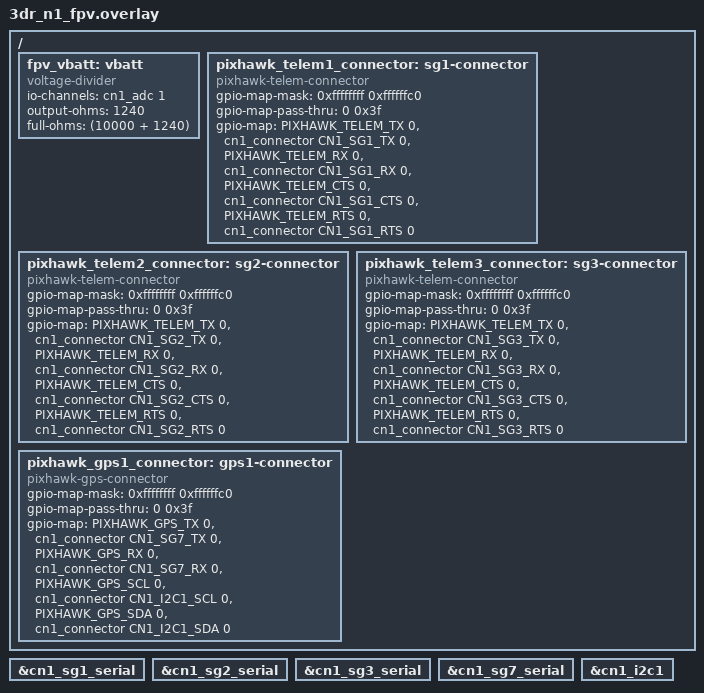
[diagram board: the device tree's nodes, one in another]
/*
 * SPDX-FileCopyrightText: Copyright The Zephyr Project Contributors
 * SPDX-License-Identifier: Apache-2.0
 */

#include <zephyr/dt-bindings/gpio/3dr-control-n1-connector.h>
#include <zephyr/dt-bindings/gpio/pixhawk-connector.h>

/ {
	/*
	 * Battery voltage from the VBATT pads. The resistors are not documented:
	 * these values give the ratio measured on a carrier, 22.5 V reading 2.483 V.
	 */
	fpv_vbatt: vbatt {
		compatible = "voltage-divider";
		io-channels = <&cn1_adc 1>;
		output-ohms = <1240>;
		full-ohms = <(10000 + 1240)>;
	};

	pixhawk_telem1_connector: sg1-connector {
		compatible = "pixhawk-telem-connector";
		#gpio-cells = <2>;
		gpio-map-mask = <0xffffffff 0xffffffc0>;
		gpio-map-pass-thru = <0 0x3f>;
		gpio-map = <PIXHAWK_TELEM_TX 0 &cn1_connector CN1_SG1_TX 0>,
			   <PIXHAWK_TELEM_RX 0 &cn1_connector CN1_SG1_RX 0>,
			   <PIXHAWK_TELEM_CTS 0 &cn1_connector CN1_SG1_CTS 0>,
			   <PIXHAWK_TELEM_RTS 0 &cn1_connector CN1_SG1_RTS 0>;
	};

	pixhawk_telem2_connector: sg2-connector {
		compatible = "pixhawk-telem-connector";
		#gpio-cells = <2>;
		gpio-map-mask = <0xffffffff 0xffffffc0>;
		gpio-map-pass-thru = <0 0x3f>;
		gpio-map = <PIXHAWK_TELEM_TX 0 &cn1_connector CN1_SG2_TX 0>,
			   <PIXHAWK_TELEM_RX 0 &cn1_connector CN1_SG2_RX 0>,
			   <PIXHAWK_TELEM_CTS 0 &cn1_connector CN1_SG2_CTS 0>,
			   <PIXHAWK_TELEM_RTS 0 &cn1_connector CN1_SG2_RTS 0>;
	};

	pixhawk_telem3_connector: sg3-connector {
		compatible = "pixhawk-telem-connector";
		#gpio-cells = <2>;
		gpio-map-mask = <0xffffffff 0xffffffc0>;
		gpio-map-pass-thru = <0 0x3f>;
		gpio-map = <PIXHAWK_TELEM_TX 0 &cn1_connector CN1_SG3_TX 0>,
			   <PIXHAWK_TELEM_RX 0 &cn1_connector CN1_SG3_RX 0>,
			   <PIXHAWK_TELEM_CTS 0 &cn1_connector CN1_SG3_CTS 0>,
			   <PIXHAWK_TELEM_RTS 0 &cn1_connector CN1_SG3_RTS 0>;
	};

	pixhawk_gps1_connector: gps1-connector {
		compatible = "pixhawk-gps-connector";
		#gpio-cells = <2>;
		gpio-map-mask = <0xffffffff 0xffffffc0>;
		gpio-map-pass-thru = <0 0x3f>;
		gpio-map = <PIXHAWK_GPS_TX 0 &cn1_connector CN1_SG7_TX 0>,
			   <PIXHAWK_GPS_RX 0 &cn1_connector CN1_SG7_RX 0>,
			   <PIXHAWK_GPS_SCL 0 &cn1_connector CN1_I2C1_SCL 0>,
			   <PIXHAWK_GPS_SDA 0 &cn1_connector CN1_I2C1_SDA 0>;
	};
};

pixhawk_telem1: &cn1_sg1_serial {};

pixhawk_telem2: &cn1_sg2_serial {};

pixhawk_telem3: &cn1_sg3_serial {};

pixhawk_gps1_serial: &cn1_sg7_serial {};

pixhawk_gps1_i2c: &cn1_i2c1 {};
